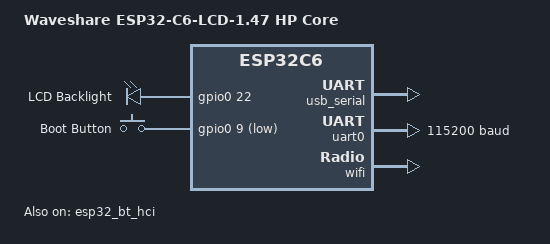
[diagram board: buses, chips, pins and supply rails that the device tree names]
/*
 * Copyright (c) 2026 Shankar Sridhar
 * SPDX-License-Identifier: Apache-2.0
 */

/dts-v1/;
#include <espressif/esp32c6/esp32c6_wroom_n4.dtsi>
#include <zephyr/dt-bindings/led/led.h>
#include <zephyr/dt-bindings/input/input-event-codes.h>
#include <espressif/partitions_0x0_default.dtsi>
#include "esp32c6_lcd_1_47_hpcore-pinctrl.dtsi"

/ {
	model = "Waveshare ESP32-C6-LCD-1.47 HP Core";
	compatible = "waveshare,esp32c6-lcd-1.47", "espressif,esp32c6";

	chosen {
		zephyr,sram = &sramhp;
		zephyr,console = &usb_serial;
		zephyr,shell-uart = &usb_serial;
		zephyr,flash = &flash0;
		zephyr,code-partition = &slot0_partition;
		zephyr,bt-hci = &esp32_bt_hci;
	};

	aliases {
		sw0 = &boot_button;
		watchdog0 = &wdt0;
		led0 = &lcd_backlight;
	};

	leds {
		compatible = "gpio-leds";

		lcd_backlight: lcd_backlight {
			gpios = <&gpio0 22 GPIO_ACTIVE_HIGH>;
			label = "LCD Backlight";
		};
	};

	gpio_keys {
		compatible = "gpio-keys";

		boot_button: button {
			label = "Boot Button";
			gpios = <&gpio0 9 (GPIO_PULL_UP | GPIO_ACTIVE_LOW)>;
			zephyr,code = <INPUT_KEY_0>;
		};
	};
};

&usb_serial {
	status = "okay";
};

&uart0 {
	status = "okay";
	current-speed = <115200>;
	pinctrl-0 = <&uart0_default>;
	pinctrl-names = "default";
};

&wifi {
	status = "okay";
};

&esp32_bt_hci {
	status = "okay";
};
